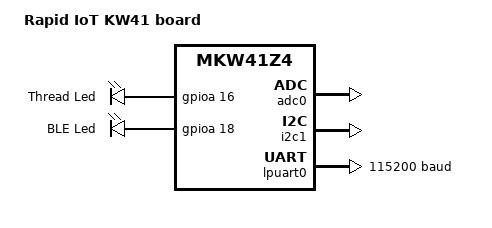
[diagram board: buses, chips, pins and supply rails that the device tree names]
/dts-v1/;

#include <nxp/nxp_kw41z.dtsi>

/ {
	model = "Rapid IoT KW41 board";
	compatible = "nxp,kw41z", "nxp,mkw41z4";

	aliases {
		adc-0 = &adc0;
		lpuart-0 = &lpuart0;
		pinmux-a = &pinmux_a;
		pinmux-b = &pinmux_b;
		pinmux-c = &pinmux_c;
		gpio-a = &gpioa;
		gpio-b = &gpiob;
		gpio-c = &gpioc;
		i2c-0 = &i2c0;
		i2c-1 = &i2c1;
		led0 = &white_led;
		led1 = &blue_led;
	};

	chosen {
		zephyr,sram = &sram0;
		zephyr,flash = &flash0;
	};
	leds {
	    compatible = "gpio-leds";
		white_led: led_0 {
			gpios = <&gpioa 16 0>;
			label = "Thread Led";
		};
		blue_led: led_1 {
			gpios = <&gpioa 18 0>;
			label = "BLE Led";
		};
	};

};

&adc0 {
	status = "ok";
};

&i2c1 {
	status = "ok";
};

&lpuart0 {
	status = "ok";
	current-speed = <115200>;
};

&flash0 {
	/*
	 * For more information, see:
	 * http://docs.zephyrproject.org/devices/dts/flash_partitions.html
	 */
	partitions {
		compatible = "fixed-partitions";
		#address-cells = <1>;
		#size-cells = <1>;

#if defined(CONFIG_FS_FLASH_STORAGE_PARTITION)
		slot0_partition: partition@c000 {
			label = "image-0";
			reg = <0x00000000 0x7d000>;
		};

		storage_partition: partition@7a000 {
			label = "storage";
			reg = <0x0007d000 0x00003000>;
		};
#else
		slot0_partition: partition@c000 {
			label = "image-0";
			reg = <0x00000000 0x80000>;
		};
#endif
	};
};

